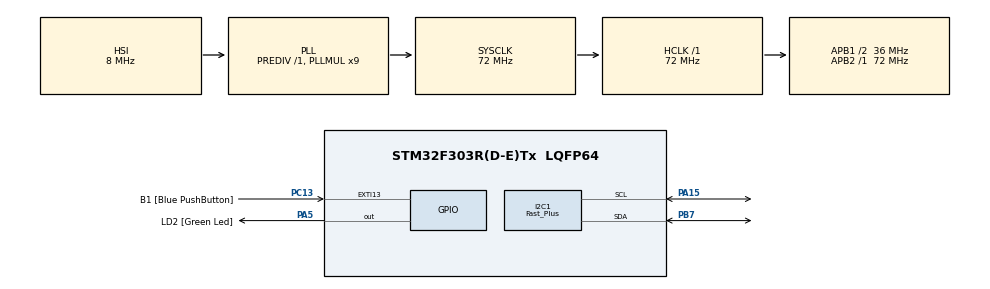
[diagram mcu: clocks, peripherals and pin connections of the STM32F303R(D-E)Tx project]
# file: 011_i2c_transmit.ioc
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Mcu.Family=STM32F3
PA2.GPIO_PuPd=GPIO_NOPULL
RCC.CortexFreq_Value=72000000
I2C1.I2C_Speed_Mode=I2C_Fast_Plus
I2C1.GeneralCallMode=I2C_GENERALCALL_DISABLE
PC13.Signal=GPXTI13
PA14.GPIO_Label=TCK
RCC.SYSCLKSourceVirtual=RCC_SYSCLKSOURCE_PLLCLK
PA3.GPIO_PuPd=GPIO_NOPULL
PA2.GPIO_Speed=GPIO_SPEED_FREQ_LOW
PC13.GPIO_Label=B1 [Blue PushButton]
RCC.APB1CLKDivider=RCC_HCLK_DIV2
PC14-OSC32_IN.Signal=RCC_OSC32_IN
PA3.GPIO_Speed=GPIO_SPEED_FREQ_LOW
ProjectManager.StackSize=0x400
PA13.Signal=SYS_JTMS-SWDIO
ProjectManager.TargetToolchain=STM32CubeIDE
PA3.GPIO_Mode=GPIO_MODE_AF_PP
RCC.HCLKFreq_Value=72000000
RCC.APB2TimFreq_Value=72000000
I2C1.Timing=0x00000001
RCC.USBFreq_Value=72000000
PC15-OSC32_OUT.Signal=RCC_OSC32_OUT
RCC.AHBFreq_Value=72000000
PF0-OSC_IN.Mode=HSE-External-Clock-Source
PA5.Signal=GPIO_Output
RCC.HSE_VALUE=8000000
board=NUCLEO-F303RE
PA15.Mode=I2C
RCC.RCC_PLLsource_Clock_Source_FROM_HSE=RCC_HSE_PREDIV_DIV2
RCC.PLLMUL=RCC_PLL_MUL9
RCC.APB2Freq_Value=72000000
PC14-OSC32_IN.Mode=LSE-External-Clock-Source
PA14.Mode=Serial_Wire
PA5.GPIO_PuPd=GPIO_NOPULL
PB7.Signal=I2C1_SDA
PA13.Mode=Serial_Wire
Mcu.Name=STM32F303R(D-E)Tx
PA2.Signal=USART2_TX
PA13.GPIO_Label=TMS
I2C1.OwnAddress=0
PB3.Signal=SYS_JTDO-TRACESWO
RCC.SYSCLKFreq_VALUE=72000000
Mcu.Package=LQFP64
PA5.GPIO_Label=LD2 [Green Led]
PC13.GPIO_ModeDefaultEXTI=GPIO_MODE_IT_FALLING
PA2.GPIO_Label=USART_TX
PB7.Mode=I2C
PA14.Signal=SYS_JTCK-SWCLK
PA15.Signal=I2C1_SCL
ProjectManager.HeapSize=0x200
RCC.HSI_VALUE=8000000
RCC.PLLP=RCC_PLLP_DIV4
PA5.GPIO_Speed=GPIO_SPEED_FREQ_LOW
RCC.PLLQ=7
NVIC.PriorityGroup=NVIC_PRIORITYGROUP_0
RCC.PLLM=8
RCC.PLLN=336
RCC.APB1TimFreq_Value=72000000
PF0-OSC_IN.Signal=RCC_OSC_IN
RCC.APB1Freq_Value=36000000
PA5.GPIO_Mode=GPIO_MODE_OUTPUT_PP
PF1-OSC_OUT.Signal=RCC_OSC_OUT
PA3.GPIO_Label=USART_RX
PA3.Signal=USART2_RX
PA2.GPIO_Mode=GPIO_MODE_AF_PP
PB3.GPIO_Label=SWO

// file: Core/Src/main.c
/* USER CODE BEGIN Header */
/**
  ******************************************************************************
  * @file           : main.c
  * @brief          : Main program body
  ******************************************************************************
  * @attention
  *
  * <h2><center>&copy; Copyright (c) 2021 STMicroelectronics.
  * All rights reserved.</center></h2>
  *
  * This software component is licensed by ST under BSD 3-Clause license,
  * the "License"; You may not use this file except in compliance with the
  * License. You may obtain a copy of the License at:
  *                        opensource.org/licenses/BSD-3-Clause
  *
  ******************************************************************************
  */
/* USER CODE END Header */
#include "main.h"

I2C_HandleTypeDef hi2c1;

/* USER CODE BEGIN PV */
uint8_t data[]="deneme";
/* USER CODE END PV */

void SystemClock_Config(void);
static void MX_GPIO_Init(void);
static void MX_I2C1_Init(void);

int main(void)
{

  /* MCU Configuration--------------------------------------------------------*/

  /* Reset of all peripherals, Initializes the Flash interface and the Systick. */
  HAL_Init();

  /* Configure the system clock */
  SystemClock_Config();

  /* Initialize all configured peripherals */
  MX_GPIO_Init();
  MX_I2C1_Init();

  /* Infinite loop */
  while (1)
  {

    /* USER CODE BEGIN 3 */
	  HAL_I2C_Master_Transmit(&hi2c1,0x08, (uint8_t*)data,sizeof(data),100);
	  HAL_GPIO_TogglePin(GPIOA, GPIO_PIN_5);
	  HAL_Delay(100);
  }
  /* USER CODE END 3 */
}

void SystemClock_Config(void)
{
  RCC_OscInitTypeDef RCC_OscInitStruct = {0};
  RCC_ClkInitTypeDef RCC_ClkInitStruct = {0};
  RCC_PeriphCLKInitTypeDef PeriphClkInit = {0};

  /** Initializes the RCC Oscillators according to the specified parameters
  * in the RCC_OscInitTypeDef structure.
  */
  RCC_OscInitStruct.OscillatorType = RCC_OSCILLATORTYPE_HSI;
  RCC_OscInitStruct.HSIState = RCC_HSI_ON;
  RCC_OscInitStruct.HSICalibrationValue = RCC_HSICALIBRATION_DEFAULT;
  RCC_OscInitStruct.PLL.PLLState = RCC_PLL_ON;
  RCC_OscInitStruct.PLL.PLLSource = RCC_PLLSOURCE_HSI;
  RCC_OscInitStruct.PLL.PLLMUL = RCC_PLL_MUL9;
  RCC_OscInitStruct.PLL.PREDIV = RCC_PREDIV_DIV1;
  if (HAL_RCC_OscConfig(&RCC_OscInitStruct) != HAL_OK)
  {
    Error_Handler();
  }
  /** Initializes the CPU, AHB and APB buses clocks
  */
  RCC_ClkInitStruct.ClockType = RCC_CLOCKTYPE_HCLK|RCC_CLOCKTYPE_SYSCLK
                              |RCC_CLOCKTYPE_PCLK1|RCC_CLOCKTYPE_PCLK2;
  RCC_ClkInitStruct.SYSCLKSource = RCC_SYSCLKSOURCE_PLLCLK;
  RCC_ClkInitStruct.AHBCLKDivider = RCC_SYSCLK_DIV1;
  RCC_ClkInitStruct.APB1CLKDivider = RCC_HCLK_DIV2;
  RCC_ClkInitStruct.APB2CLKDivider = RCC_HCLK_DIV1;

  if (HAL_RCC_ClockConfig(&RCC_ClkInitStruct, FLASH_LATENCY_2) != HAL_OK)
  {
    Error_Handler();
  }
  PeriphClkInit.PeriphClockSelection = RCC_PERIPHCLK_I2C1;
  PeriphClkInit.I2c1ClockSelection = RCC_I2C1CLKSOURCE_HSI;
  if (HAL_RCCEx_PeriphCLKConfig(&PeriphClkInit) != HAL_OK)
  {
    Error_Handler();
  }
}

static void MX_I2C1_Init(void)
{

  hi2c1.Instance = I2C1;
  hi2c1.Init.Timing = 0x00000001;
  hi2c1.Init.OwnAddress1 = 0;
  hi2c1.Init.AddressingMode = I2C_ADDRESSINGMODE_7BIT;
  hi2c1.Init.DualAddressMode = I2C_DUALADDRESS_DISABLE;
  hi2c1.Init.OwnAddress2 = 0;
  hi2c1.Init.OwnAddress2Masks = I2C_OA2_NOMASK;
  hi2c1.Init.GeneralCallMode = I2C_GENERALCALL_DISABLE;
  hi2c1.Init.NoStretchMode = I2C_NOSTRETCH_DISABLE;
  if (HAL_I2C_Init(&hi2c1) != HAL_OK)
  {
    Error_Handler();
  }
  /** Configure Analogue filter
  */
  if (HAL_I2CEx_ConfigAnalogFilter(&hi2c1, I2C_ANALOGFILTER_ENABLE) != HAL_OK)
  {
    Error_Handler();
  }
  /** Configure Digital filter
  */
  if (HAL_I2CEx_ConfigDigitalFilter(&hi2c1, 0) != HAL_OK)
  {
    Error_Handler();
  }
  /** I2C Fast mode Plus enable
  */
  __HAL_SYSCFG_FASTMODEPLUS_ENABLE(I2C_FASTMODEPLUS_I2C1);

}

static void MX_GPIO_Init(void)
{
  GPIO_InitTypeDef GPIO_InitStruct = {0};

  /* GPIO Ports Clock Enable */
  __HAL_RCC_GPIOC_CLK_ENABLE();
  __HAL_RCC_GPIOF_CLK_ENABLE();
  __HAL_RCC_GPIOA_CLK_ENABLE();
  __HAL_RCC_GPIOB_CLK_ENABLE();

  /*Configure GPIO pin Output Level */
  HAL_GPIO_WritePin(LD2_GPIO_Port, LD2_Pin, GPIO_PIN_RESET);

  /*Configure GPIO pin : B1_Pin */
  GPIO_InitStruct.Pin = B1_Pin;
  GPIO_InitStruct.Mode = GPIO_MODE_IT_FALLING;
  GPIO_InitStruct.Pull = GPIO_NOPULL;
  HAL_GPIO_Init(B1_GPIO_Port, &GPIO_InitStruct);

  /*Configure GPIO pins : USART_TX_Pin USART_RX_Pin */
  GPIO_InitStruct.Pin = USART_TX_Pin|USART_RX_Pin;
  GPIO_InitStruct.Mode = GPIO_MODE_AF_PP;
  GPIO_InitStruct.Pull = GPIO_NOPULL;
  GPIO_InitStruct.Speed = GPIO_SPEED_FREQ_LOW;
  GPIO_InitStruct.Alternate = GPIO_AF7_USART2;
  HAL_GPIO_Init(GPIOA, &GPIO_InitStruct);

  /*Configure GPIO pin : LD2_Pin */
  GPIO_InitStruct.Pin = LD2_Pin;
  GPIO_InitStruct.Mode = GPIO_MODE_OUTPUT_PP;
  GPIO_InitStruct.Pull = GPIO_NOPULL;
  GPIO_InitStruct.Speed = GPIO_SPEED_FREQ_LOW;
  HAL_GPIO_Init(LD2_GPIO_Port, &GPIO_InitStruct);

}

void Error_Handler(void)
{
  __disable_irq();
  while (1)
  {
  }
}

/************************ (C) COPYRIGHT STMicroelectronics *****END OF FILE****/
